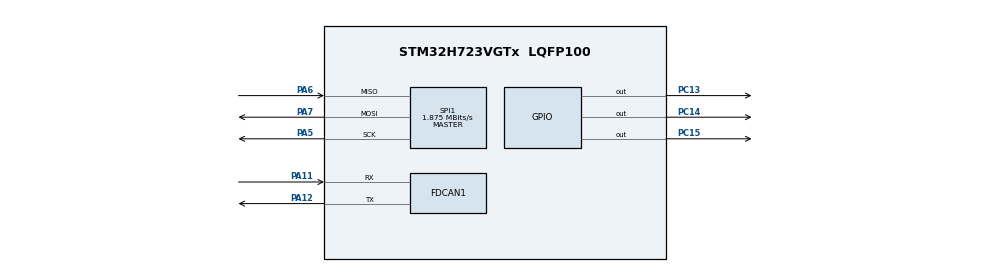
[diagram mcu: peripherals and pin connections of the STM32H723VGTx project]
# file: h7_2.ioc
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FDCAN1.AutoRetransmission=ENABLE
FDCAN1.DataPrescaler=3
FDCAN1.DataSyncJumpWidth=10
FDCAN1.FrameFormat=FDCAN_FRAME_CLASSIC
FDCAN1.NominalPrescaler=3
FDCAN1.NominalSyncJumpWidth=10
FDCAN1.NominalTimeSeg1=29
FDCAN1.NominalTimeSeg2=10
FDCAN1.RxFifo0ElmtsNbr=16
FDCAN1.StdFiltersNbr=1
FDCAN1.TxFifoQueueElmtsNbr=8
Mcu.Family=STM32H7
Mcu.Name=STM32H723VGTx
Mcu.Package=LQFP100
NVIC.PriorityGroup=NVIC_PRIORITYGROUP_4
NVIC.TIM6_DAC_IRQn=true\:0\:0\:false\:false\:true\:true\:true
PA11.Mode=FDCAN_Activate
PA11.Signal=FDCAN1_RX
PA12.Mode=FDCAN_Activate
PA12.Signal=FDCAN1_TX
PA13(JTMS/SWDIO).Mode=Serial_Wire
PA13(JTMS/SWDIO).Signal=DEBUG_JTMS-SWDIO
PA14(JTCK/SWCLK).Mode=Serial_Wire
PA14(JTCK/SWCLK).Signal=DEBUG_JTCK-SWCLK
PA5.Mode=Full_Duplex_Master
PA5.Signal=SPI1_SCK
PA6.Mode=Full_Duplex_Master
PA6.Signal=SPI1_MISO
PA7.Mode=Full_Duplex_Master
PA7.Signal=SPI1_MOSI
PC13.GPIO_ModeDefaultOutputPP=GPIO_MODE_OUTPUT_PP
PC13.GPIO_PuPd=GPIO_NOPULL
PC13.GPIO_Speed=GPIO_SPEED_FREQ_LOW
PC13.PinState=GPIO_PIN_SET
PC13.Signal=GPIO_Output
PC14-OSC32_IN.GPIO_ModeDefaultOutputPP=GPIO_MODE_OUTPUT_PP
PC14-OSC32_IN.GPIO_PuPd=GPIO_NOPULL
PC14-OSC32_IN.GPIO_Speed=GPIO_SPEED_FREQ_LOW
PC14-OSC32_IN.PinState=GPIO_PIN_SET
PC14-OSC32_IN.Signal=GPIO_Output
PC15-OSC32_OUT.GPIO_ModeDefaultOutputPP=GPIO_MODE_OUTPUT_PP
PC15-OSC32_OUT.GPIO_PuPd=GPIO_NOPULL
PC15-OSC32_OUT.GPIO_Speed=GPIO_SPEED_FREQ_LOW
PC15-OSC32_OUT.PinState=GPIO_PIN_SET
PC15-OSC32_OUT.Signal=GPIO_Output
PH0-OSC_IN.Mode=HSE-External-Oscillator
PH0-OSC_IN.Signal=RCC_OSC_IN
PH1-OSC_OUT.Mode=HSE-External-Oscillator
PH1-OSC_OUT.Signal=RCC_OSC_OUT
ProjectManager.HeapSize=0x200
ProjectManager.StackSize=0x400
ProjectManager.TargetToolchain=MDK-ARM V5.32
RCC.ADCFreq_Value=160000000
RCC.APB1Freq_Value=120000000
RCC.APB2Freq_Value=120000000
RCC.APB3Freq_Value=120000000
RCC.APB4Freq_Value=120000000
RCC.CortexFreq_Value=480000000
RCC.D1PPRE=RCC_APB3_DIV2
RCC.D2PPRE1=RCC_APB1_DIV2
RCC.D2PPRE2=RCC_APB2_DIV2
RCC.D3PPRE=RCC_APB4_DIV2
RCC.DIVM1=2
RCC.DIVM2=12
RCC.DIVM3=24
RCC.DIVN1=40
RCC.DIVN2=160
RCC.DIVN3=160
RCC.DIVP1=1
RCC.DIVQ1=4
RCC.HCLKFreq_Value=240000000
RCC.HPRE=RCC_HCLK_DIV2
RCC.HSE_VALUE=24000000
RCC.PLLFRACN=0
RCC.PLLSourceVirtual=RCC_PLLSOURCE_HSE
RCC.SYSCLKFreq_VALUE=480000000
RCC.SYSCLKSource=RCC_SYSCLKSOURCE_PLLCLK
RCC.USBFreq_Value=120000000
SPI1.BaudRatePrescaler=SPI_BAUDRATEPRESCALER_64
SPI1.CalculateBaudRate=1.875 MBits/s
SPI1.DataSize=SPI_DATASIZE_8BIT
SPI1.Direction=SPI_DIRECTION_2LINES
SPI1.Mode=SPI_MODE_MASTER
SPI1.VirtualType=VM_MASTER
TIM6.Period=10000-1
TIM6.Prescaler=240-1
VP_TIM6_VS_ClockSourceINT.Mode=Enable_Timer
board=custom

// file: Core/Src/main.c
/* USER CODE BEGIN Header */
/**
  ******************************************************************************
  * @file           : main.c
  * @brief          : Main program body
  ******************************************************************************
  * @attention
  *
  * <h2><center>&copy; Copyright (c) 2026 STMicroelectronics.
  * All rights reserved.</center></h2>
  *
  * This software component is licensed by ST under BSD 3-Clause license,
  * the "License"; You may not use this file except in compliance with the
  * License. You may obtain a copy of the License at:
  *                        opensource.org/licenses/BSD-3-Clause
  *
  ******************************************************************************
  */
/* USER CODE END Header */
#include "main.h"
#include "fdcan.h"
#include "spi.h"
#include "tim.h"
#include "gpio.h"

/* USER CODE BEGIN Includes */
#include "1_Middleware/Algorithm/Basic/alg_basic.h"
#include "1_Middleware/Algorithm/PID/alg_pid.h"
#include "1_Middleware/Driver/CAN/drv_can.h"
#include "2_Device/Motor/Motor_DJI/dvc_motor_dji.h"
#include "4_Task/tsk_config_and_callback.h"
/* USER CODE END Includes */

void SystemClock_Config(void);

int main(void)
{

  /* MCU Configuration--------------------------------------------------------*/

  /* Reset of all peripherals, Initializes the Flash interface and the Systick. */

  /* USER CODE BEGIN Init */
  HAL_Init();

  /* USER CODE END Init */

  /* Configure the system clock */
  SystemClock_Config();

  /* Initialize all configured peripherals */
  MX_GPIO_Init();
  MX_FDCAN1_Init();
  MX_TIM6_Init();
  MX_SPI1_Init();
  /* USER CODE BEGIN 2 */

	  Task_Init();

  /* USER CODE END 2 */

  /* Infinite loop */
  /* USER CODE BEGIN WHILE */
  while (1)
  {
	Task_Loop();
    /* USER CODE END WHILE */

  }
}

void SystemClock_Config(void)
{
  RCC_OscInitTypeDef RCC_OscInitStruct = {0};
  RCC_ClkInitTypeDef RCC_ClkInitStruct = {0};

  /** Supply configuration update enable
  */
  HAL_PWREx_ConfigSupply(PWR_LDO_SUPPLY);
  /** Configure the main internal regulator output voltage
  */
  __HAL_PWR_VOLTAGESCALING_CONFIG(PWR_REGULATOR_VOLTAGE_SCALE0);

  while(!__HAL_PWR_GET_FLAG(PWR_FLAG_VOSRDY)) {}
  /** Initializes the RCC Oscillators according to the specified parameters
  * in the RCC_OscInitTypeDef structure.
  */
  RCC_OscInitStruct.OscillatorType = RCC_OSCILLATORTYPE_HSE;
  RCC_OscInitStruct.HSEState = RCC_HSE_ON;
  RCC_OscInitStruct.PLL.PLLState = RCC_PLL_ON;
  RCC_OscInitStruct.PLL.PLLSource = RCC_PLLSOURCE_HSE;
  RCC_OscInitStruct.PLL.PLLM = 2;
  RCC_OscInitStruct.PLL.PLLN = 40;
  RCC_OscInitStruct.PLL.PLLP = 1;
  RCC_OscInitStruct.PLL.PLLQ = 4;
  RCC_OscInitStruct.PLL.PLLR = 2;
  RCC_OscInitStruct.PLL.PLLRGE = RCC_PLL1VCIRANGE_3;
  RCC_OscInitStruct.PLL.PLLVCOSEL = RCC_PLL1VCOWIDE;
  RCC_OscInitStruct.PLL.PLLFRACN = 0;
  if (HAL_RCC_OscConfig(&RCC_OscInitStruct) != HAL_OK)
  {
    Error_Handler();
  }
  /** Initializes the CPU, AHB and APB buses clocks
  */
  RCC_ClkInitStruct.ClockType = RCC_CLOCKTYPE_HCLK|RCC_CLOCKTYPE_SYSCLK
                              |RCC_CLOCKTYPE_PCLK1|RCC_CLOCKTYPE_PCLK2
                              |RCC_CLOCKTYPE_D3PCLK1|RCC_CLOCKTYPE_D1PCLK1;
  RCC_ClkInitStruct.SYSCLKSource = RCC_SYSCLKSOURCE_PLLCLK;
  RCC_ClkInitStruct.SYSCLKDivider = RCC_SYSCLK_DIV1;
  RCC_ClkInitStruct.AHBCLKDivider = RCC_HCLK_DIV2;
  RCC_ClkInitStruct.APB3CLKDivider = RCC_APB3_DIV2;
  RCC_ClkInitStruct.APB1CLKDivider = RCC_APB1_DIV2;
  RCC_ClkInitStruct.APB2CLKDivider = RCC_APB2_DIV2;
  RCC_ClkInitStruct.APB4CLKDivider = RCC_APB4_DIV2;

  if (HAL_RCC_ClockConfig(&RCC_ClkInitStruct, FLASH_LATENCY_3) != HAL_OK)
  {
    Error_Handler();
  }
}

void Error_Handler(void)
{
  __disable_irq();
  while (1)
  {
  }
}

/************************ (C) COPYRIGHT STMicroelectronics *****END OF FILE****/
